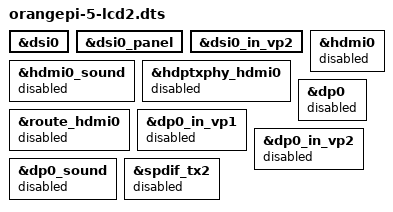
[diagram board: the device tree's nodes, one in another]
/dts-v1/;
/plugin/;

/ {
	fragment@0 {
		target = <&dsi0>;
		__overlay__ {
			status = "okay";
		};
	};

	fragment@1 {
		target = <&dsi0_panel>;
		__overlay__ {
			status = "okay";
		};
	};

	fragment@2 {
		target = <&dsi0_in_vp2>;
		__overlay__ {
			status = "okay";
		};
	};

	fragment@3 {
		target = <&hdmi0>;
		__overlay__ {
			status = "disabled";
		};
	};

	fragment@4 {
		target = <&hdmi0_sound>;
		__overlay__ {
			status = "disabled";
		};
	};

	fragment@5 {
		target = <&hdptxphy_hdmi0>;
		__overlay__ {
			status = "disabled";
		};
	};

	fragment@6 {
		target = <&route_hdmi0>;
		__overlay__ {
			status = "disabled";
		};
	};

	fragment@7 {
		target = <&dp0>;
		__overlay__ {
			status = "disabled";
		};
	};

	fragment@8 {
		target = <&dp0_in_vp1>;
		__overlay__ {
			status = "disabled";
		};
	};

	fragment@9 {
		target = <&dp0_in_vp2>;
		__overlay__ {
			status = "disabled";
		};
	};

	fragment@10 {
		target = <&dp0_sound>;
		__overlay__ {
			status = "disabled";
		};
	};

	fragment@11 {
		target = <&spdif_tx2>;
		__overlay__ {
			status = "disabled";
		};
	};
};
